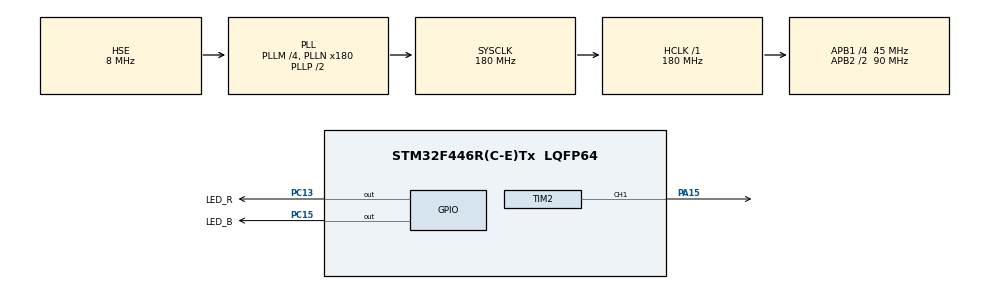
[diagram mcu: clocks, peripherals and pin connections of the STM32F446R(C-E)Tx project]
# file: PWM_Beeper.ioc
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Mcu.Family=STM32F4
Mcu.Name=STM32F446R(C-E)Tx
Mcu.Package=LQFP64
NVIC.PriorityGroup=NVIC_PRIORITYGROUP_4
NVIC.TIM6_DAC_IRQn=true\:0\:0\:false\:false\:true\:true\:true\:true
PA13.Mode=Serial_Wire
PA13.Signal=SYS_JTMS-SWDIO
PA14.Mode=Serial_Wire
PA14.Signal=SYS_JTCK-SWCLK
PA15.Signal=S_TIM2_CH1_ETR
PC13.GPIO_Label=LED_R
PC13.GPIO_ModeDefaultOutputPP=GPIO_MODE_OUTPUT_OD
PC13.GPIO_PuPd=GPIO_NOPULL
PC13.PinState=GPIO_PIN_SET
PC13.Signal=GPIO_Output
PC15-OSC32_OUT.GPIO_Label=LED_B
PC15-OSC32_OUT.GPIO_ModeDefaultOutputPP=GPIO_MODE_OUTPUT_OD
PC15-OSC32_OUT.GPIO_PuPd=GPIO_NOPULL
PC15-OSC32_OUT.PinState=GPIO_PIN_SET
PC15-OSC32_OUT.Signal=GPIO_Output
PH0-OSC_IN.Mode=HSE-External-Oscillator
PH0-OSC_IN.Signal=RCC_OSC_IN
PH1-OSC_OUT.Mode=HSE-External-Oscillator
PH1-OSC_OUT.Signal=RCC_OSC_OUT
ProjectManager.HeapSize=0x200
ProjectManager.StackSize=0x400
ProjectManager.TargetToolchain=Makefile
RCC.AHBFreq_Value=180000000
RCC.APB1CLKDivider=RCC_HCLK_DIV4
RCC.APB1Freq_Value=45000000
RCC.APB1TimFreq_Value=90000000
RCC.APB2CLKDivider=RCC_HCLK_DIV2
RCC.APB2Freq_Value=90000000
RCC.APB2TimFreq_Value=180000000
RCC.CortexFreq_Value=180000000
RCC.HCLKFreq_Value=180000000
RCC.HSE_VALUE=8000000
RCC.PLLM=4
RCC.PLLN=180
RCC.PLLSourceVirtual=RCC_PLLSOURCE_HSE
RCC.RCC_RTC_Clock_SourceVirtual=RCC_RTCCLKSOURCE_HSE_DIV25
RCC.RCC_RTC_Clock_Source_FROM_HSE=RCC_RTCCLKSOURCE_HSE_DIV25
RCC.SYSCLKFreq_VALUE=180000000
RCC.SYSCLKSource=RCC_SYSCLKSOURCE_PLLCLK
RCC.USBFreq_Value=180000000
RCC.VCOOutputFreq_Value=360000000
SH.S_TIM2_CH1_ETR.0=TIM2_CH1,PWM Generation1 CH1
TIM2.AutoReloadPreload=TIM_AUTORELOAD_PRELOAD_ENABLE
TIM2.Channel-PWM\ Generation1\ CH1=TIM_CHANNEL_1
TIM2.Period=899
TIM2.Prescaler=381
TIM2.Pulse-PWM\ Generation1\ CH1=180
TIM6.Period=4999
TIM6.Prescaler=8999
VP_TIM2_VS_ClockSourceINT.Mode=Internal
VP_TIM6_VS_ClockSourceINT.Mode=Enable_Timer
board=custom

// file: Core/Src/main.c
/* USER CODE BEGIN Header */
/**
 ******************************************************************************
 * @file           : main.c
 * @brief          : Main program body
 ******************************************************************************
 * @attention
 *
 * Copyright (c) 2024 STMicroelectronics.
 * All rights reserved.
 *
 * This software is licensed under terms that can be found in the LICENSE file
 * in the root directory of this software component.
 * If no LICENSE file comes with this software, it is provided AS-IS.
 *
 ******************************************************************************
 */
/* USER CODE END Header */
#include "main.h"
#include "gpio.h"
#include "tim.h"

/* USER CODE BEGIN PD */

#define BEEPER_VOLUME 15

/* USER CODE END PD */

/* USER CODE BEGIN PV */

const float frequency_n1[] = {
    130.81278, 146.83238, 164.81378, 174.61412, 195.99772, 220.00000, 246.94165,
};

const float frequency_0[] = {
    261.62557, 293.66477, 329.62756, 349.22823, 391.99543, 440.00000, 493.88330,
};

const float frequency_1[] = {
    523.25113, 587.32953, 659.25512, 698.45646, 783.99087, 880.00000, 987.76660,
};

/* USER CODE END PV */

void SystemClock_Config(void);
/* USER CODE BEGIN PFP */

void set_prescaler(float frequency) // 通过设置预分频器来得到需要的频率
{
  __HAL_TIM_SET_PRESCALER(&htim2, (uint32_t)(100000.0 / frequency) - 1);
}

void set_volume(uint8_t volume) // 0~100
{
  // mapping: 0~100 -> 0~900
  __HAL_TIM_SET_COMPARE(&htim2, TIM_CHANNEL_1, volume * 9);
}

void play(float frequency, uint32_t duration) {
  HAL_GPIO_WritePin(GPIOC, LED_R_Pin, GPIO_PIN_RESET);
  if (frequency >= 0.0) // 小于零不改变频率
  {
    set_prescaler(frequency);
  }
  HAL_Delay(duration - 80);
  HAL_GPIO_WritePin(GPIOC, LED_R_Pin, GPIO_PIN_SET);
  HAL_Delay(80);
  set_volume(0);
  HAL_Delay(20);
  set_volume(BEEPER_VOLUME);
}

void HAL_TIM_PeriodElapsedCallback(TIM_HandleTypeDef *htim) {
  if (htim->Instance == TIM6) {
    HAL_GPIO_TogglePin(GPIOC, LED_B_Pin);
  }
}

/* USER CODE END PFP */

int main(void) {

  /* MCU Configuration--------------------------------------------------------*/

  /* Reset of all peripherals, Initializes the Flash interface and the Systick.
   */
  HAL_Init();

  /* Configure the system clock */
  SystemClock_Config();

  /* Initialize all configured peripherals */
  MX_GPIO_Init();
  MX_TIM2_Init();
  MX_TIM6_Init();
  /* USER CODE BEGIN 2 */

  HAL_TIM_Base_Start_IT(&htim6);
  HAL_TIM_PWM_Start(&htim2, TIM_CHANNEL_1);
  set_volume(BEEPER_VOLUME);

  /* USER CODE END 2 */

  /* Infinite loop */
  /* USER CODE BEGIN WHILE */
  while (1) {
    // 播放扬基歌
    play(frequency_0[0], 480);  // 1
    play(-1.0, 480);            // 1
    play(frequency_0[1], 480);  // 2
    play(frequency_0[2], 480);  // 3
    play(frequency_0[0], 480);  // 1
    play(frequency_0[2], 480);  // 3
    play(frequency_0[1], 480);  // 2
    play(frequency_n1[4], 480); //.5

    play(frequency_0[0], 480);  // 1
    play(-1.0, 480);            // 1
    play(frequency_0[1], 480);  // 2
    play(frequency_0[2], 480);  // 3
    play(frequency_0[0], 980);  // 1 -
    play(frequency_n1[6], 480); // .7
    play(frequency_n1[4], 480); // .5

    play(frequency_0[0], 480); // 1
    play(-1.0, 480);           // 1
    play(frequency_0[1], 480); // 2
    play(frequency_0[2], 480); // 3
    play(frequency_0[3], 480); // 4
    play(frequency_0[2], 480); // 3
    play(frequency_0[1], 480); // 2
    play(frequency_0[0], 480); // 1

    play(frequency_n1[6], 480); // .7
    play(frequency_n1[4], 480); // .5
    play(frequency_n1[5], 480); // .6
    play(frequency_n1[6], 480); // .7
    play(frequency_0[0], 980);  // 1 -
    play(-1.0, 980);            // 1 -

    /* USER CODE END WHILE */

    /* USER CODE BEGIN 3 */

    // 歇一秒
    set_volume(0);
    HAL_Delay(1000);
    set_volume(BEEPER_VOLUME);
  }
  /* USER CODE END 3 */
}

void SystemClock_Config(void) {
  RCC_OscInitTypeDef RCC_OscInitStruct = {0};
  RCC_ClkInitTypeDef RCC_ClkInitStruct = {0};

  /** Configure the main internal regulator output voltage
   */
  __HAL_RCC_PWR_CLK_ENABLE();
  __HAL_PWR_VOLTAGESCALING_CONFIG(PWR_REGULATOR_VOLTAGE_SCALE1);

  /** Initializes the RCC Oscillators according to the specified parameters
   * in the RCC_OscInitTypeDef structure.
   */
  RCC_OscInitStruct.OscillatorType = RCC_OSCILLATORTYPE_HSE;
  RCC_OscInitStruct.HSEState = RCC_HSE_ON;
  RCC_OscInitStruct.PLL.PLLState = RCC_PLL_ON;
  RCC_OscInitStruct.PLL.PLLSource = RCC_PLLSOURCE_HSE;
  RCC_OscInitStruct.PLL.PLLM = 4;
  RCC_OscInitStruct.PLL.PLLN = 180;
  RCC_OscInitStruct.PLL.PLLP = RCC_PLLP_DIV2;
  RCC_OscInitStruct.PLL.PLLQ = 2;
  RCC_OscInitStruct.PLL.PLLR = 2;
  if (HAL_RCC_OscConfig(&RCC_OscInitStruct) != HAL_OK) {
    Error_Handler();
  }

  /** Activate the Over-Drive mode
   */
  if (HAL_PWREx_EnableOverDrive() != HAL_OK) {
    Error_Handler();
  }

  /** Initializes the CPU, AHB and APB buses clocks
   */
  RCC_ClkInitStruct.ClockType = RCC_CLOCKTYPE_HCLK | RCC_CLOCKTYPE_SYSCLK |
                                RCC_CLOCKTYPE_PCLK1 | RCC_CLOCKTYPE_PCLK2;
  RCC_ClkInitStruct.SYSCLKSource = RCC_SYSCLKSOURCE_PLLCLK;
  RCC_ClkInitStruct.AHBCLKDivider = RCC_SYSCLK_DIV1;
  RCC_ClkInitStruct.APB1CLKDivider = RCC_HCLK_DIV4;
  RCC_ClkInitStruct.APB2CLKDivider = RCC_HCLK_DIV2;

  if (HAL_RCC_ClockConfig(&RCC_ClkInitStruct, FLASH_LATENCY_5) != HAL_OK) {
    Error_Handler();
  }
}

void Error_Handler(void) {
  __disable_irq();
  while (1) {
  }
}

#ifdef USE_FULL_ASSERT
/**
 * @brief  Reports the name of the source file and the source line number
 *         where the assert_param error has occurred.
 * @param  file: pointer to the source file name
 * @param  line: assert_param error line source number
 * @retval None
 */
void assert_failed(uint8_t *file, uint32_t line) {
  /* USER CODE BEGIN 6 */
  /* User can add his own implementation to report the file name and line
     number, ex: printf("Wrong parameters value: file %s on line %d\r\n", file,
     line) */
  /* USER CODE END 6 */
}
#endif /* USE_FULL_ASSERT */
